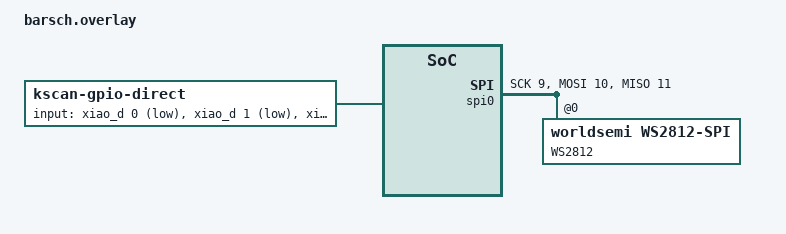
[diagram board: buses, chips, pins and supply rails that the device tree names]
#include <dt-bindings/gpio/gpio.h>
#include <dt-bindings/led/led.h>

/ {
    chosen {
        zmk,kscan = &kscan0;
        zmk,underglow = &led_strip;
    };

    kscan0: kscan {
        compatible = "zmk,kscan-gpio-direct";
        label = "KSCAN";
        input-gpios = <&xiao_d 0 (GPIO_ACTIVE_LOW | GPIO_PULL_UP)>,
                      <&xiao_d 1 (GPIO_ACTIVE_LOW | GPIO_PULL_UP)>,
                      <&xiao_d 2 (GPIO_ACTIVE_LOW | GPIO_PULL_UP)>,
                      <&xiao_d 3 (GPIO_ACTIVE_LOW | GPIO_PULL_UP)>,
                      <&xiao_d 4 (GPIO_ACTIVE_LOW | GPIO_PULL_UP)>,
                      <&xiao_d 7 (GPIO_ACTIVE_LOW | GPIO_PULL_UP)>,
                      <&xiao_d 8 (GPIO_ACTIVE_LOW | GPIO_PULL_UP)>;
    };
};

&spi0 {
    compatible = "nordic,nrf-spim";
    status = "okay";
    sck-pin = <9>;
    mosi-pin = <10>;
    miso-pin = <11>;

    led_strip: ws2812@0 {
        compatible = "worldsemi,ws2812-spi";
        label = "WS2812";
        /* SPI-bus wird über das SPI-Interface gesteuert, kein in-gpios nötig */
        chain-length = <2>;
        color-mapping = <0x010203>; /* GRB Hard-coded als Hex zur Fehlervermeidung */
    };
};
